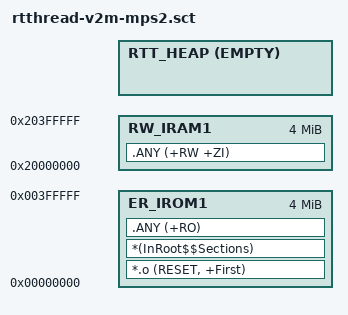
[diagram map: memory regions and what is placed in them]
#! armcc -E
; *************************************************************
; *** Scatter-Loading Description File generated by uVision ***
; *************************************************************

#define ROM_START 			0x00000000
#define ROM_SIZE			0x00400000

#define RAM1_START			0x20000000
#define RAM1_SIZE			0x00400000

#define RTT_HEAP_SIZE                   \
    (RAM1_SIZE - ImageLength(RW_IRAM1))

LR_IROM1 ROM_START ROM_SIZE  {    ; load region size_region
  ER_IROM1 ROM_START ROM_SIZE  {  ; load address = execution address
   *.o (RESET, +First)
   *(InRoot$$Sections)
   .ANY (+RO)
  }
  RW_IRAM1 RAM1_START RAM1_SIZE  {  ; RW data
   .ANY (+RW +ZI)
  }
  RTT_HEAP +0 EMPTY RTT_HEAP_SIZE {
  }
}
